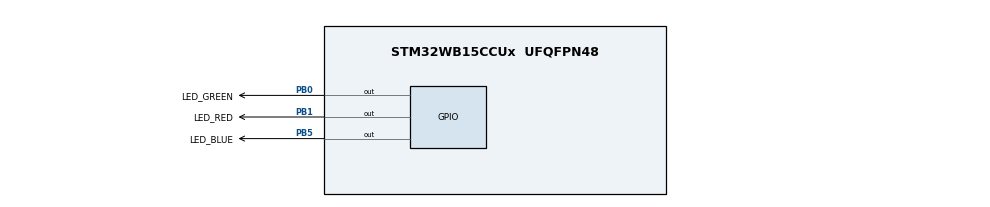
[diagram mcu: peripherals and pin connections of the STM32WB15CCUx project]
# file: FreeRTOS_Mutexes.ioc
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FREERTOS.HEAP_NUMBER=4
FREERTOS.INCLUDE_eTaskGetState=1
FREERTOS.INCLUDE_pcTaskGetTaskName=0
FREERTOS.INCLUDE_uxTaskGetStackHighWaterMark=1
FREERTOS.INCLUDE_uxTaskGetStackHighWaterMark2=0
FREERTOS.INCLUDE_uxTaskPriorityGet=1
FREERTOS.INCLUDE_vTaskCleanUpResources=0
FREERTOS.INCLUDE_vTaskDelay=1
FREERTOS.INCLUDE_vTaskDelayUntil=0
FREERTOS.INCLUDE_vTaskDelete=1
FREERTOS.INCLUDE_vTaskPrioritySet=1
FREERTOS.INCLUDE_vTaskSuspend=1
FREERTOS.INCLUDE_xEventGroupSetBitFromISR=0
FREERTOS.INCLUDE_xQueueGetMutexHolder=1
FREERTOS.INCLUDE_xSemaphoreGetMutexHolder=0
FREERTOS.INCLUDE_xTaskAbortDelay=0
FREERTOS.INCLUDE_xTaskGetCurrentTaskHandle=1
FREERTOS.INCLUDE_xTaskGetHandle=0
FREERTOS.INCLUDE_xTaskResumeFromISR=1
FREERTOS.MEMORY_ALLOCATION=0
FREERTOS.Mutexes01=osMutex
FREERTOS.Tasks01=MutHigh,16,128,MutexHighPriorityThreadr,Default,NULL,Dynamic,NULL,NULL;MutMedium,8,128,MutexMediumPriorityThread,Default,NULL,Dynamic,NULL,NULL;MutLow,8,128,MutexLowPriorityThread,Default,NULL,Dynamic,NULL,NULL
FREERTOS.configCHECK_FOR_STACK_OVERFLOW=0
FREERTOS.configENABLE_BACKWARD_COMPATIBILITY=1
FREERTOS.configENABLE_FPU=0
FREERTOS.configGENERATE_RUN_TIME_STATS=0
FREERTOS.configIDLE_SHOULD_YIELD=1
FREERTOS.configLIBRARY_LOWEST_INTERRUPT_PRIORITY=15
FREERTOS.configLIBRARY_MAX_SYSCALL_INTERRUPT_PRIORITY=5
FREERTOS.configMAX_CO_ROUTINE_PRIORITIES=2
FREERTOS.configMAX_PRIORITIES=56
FREERTOS.configMAX_TASK_NAME_LEN=16
FREERTOS.configMINIMAL_STACK_SIZE=128
FREERTOS.configQUEUE_REGISTRY_SIZE=8
FREERTOS.configRECORD_STACK_HIGH_ADDRESS=0
FREERTOS.configTICK_RATE_HZ=1000
FREERTOS.configTOTAL_HEAP_SIZE=3072
FREERTOS.configUSE_APPLICATION_TASK_TAG=0
FREERTOS.configUSE_COUNTING_SEMAPHORES=1
FREERTOS.configUSE_CO_ROUTINES=0
FREERTOS.configUSE_DAEMON_TASK_STARTUP_HOOK=0
FREERTOS.configUSE_IDLE_HOOK=0
FREERTOS.configUSE_MALLOC_FAILED_HOOK=0
FREERTOS.configUSE_MUTEXES=1
FREERTOS.configUSE_NEWLIB_REENTRANT=0
FREERTOS.configUSE_POSIX_ERRNO=0
FREERTOS.configUSE_PREEMPTION=0
FREERTOS.configUSE_RECURSIVE_MUTEXES=1
FREERTOS.configUSE_STATS_FORMATTING_FUNCTIONS=0
FREERTOS.configUSE_TASK_NOTIFICATIONS=1
FREERTOS.configUSE_TICKLESS_IDLE=0
FREERTOS.configUSE_TICK_HOOK=0
FREERTOS.configUSE_TIMERS=0
FREERTOS.configUSE_TRACE_FACILITY=1
FREERTOS.copyHeapFile=1
Mcu.Family=STM32WB
Mcu.Name=STM32WB15CCUx
Mcu.Package=UFQFPN48
NVIC.PriorityGroup=NVIC_PRIORITYGROUP_4
NVIC.TIM2_IRQn=true\:0\:0\:false\:false\:true\:false\:true\:true\:true
NVIC.TimeBase=TIM2_IRQn
NVIC.TimeBaseIP=TIM2
PB0.GPIO_Label=LED_GREEN
PB0.Signal=GPIO_Output
PB1.GPIO_Label=LED_RED
PB1.Signal=GPIO_Output
PB5.GPIO_Label=LED_BLUE
PB5.Signal=GPIO_Output
ProjectManager.HeapSize=0x200
ProjectManager.StackSize=0x400
ProjectManager.TargetToolchain=EWARM V9.60
RCC.AHB2CLKDivider=RCC_SYSCLK_DIV2
RCC.AHBFreq_Value=64000000
RCC.APB1Freq_Value=64000000
RCC.APB1TimFreq_Value=64000000
RCC.APB2Freq_Value=64000000
RCC.APB2TimFreq_Value=64000000
RCC.APB3Freq_Value=16000000
RCC.CortexFreq_Value=64000000
RCC.HCLKFreq_Value=64000000
RCC.HSE_VALUE=8000000
RCC.HSI_VALUE=16000000
RCC.LSE_VALUE=32768
RCC.PLLN=32
RCC.SYSCLKFreq_VALUE=64000000
RCC.SYSCLKSource=RCC_SYSCLKSOURCE_PLLCLK
RCC.VCOOutputFreq_Value=128000000
VP_FREERTOS_VS_CMSIS_V2.Mode=CMSIS_V2
VP_MEMORYMAP_VS_MEMORYMAP.Mode=CurAppReg
VP_SYS_VS_tim2.Mode=TIM2
board=custom

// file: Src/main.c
/* USER CODE BEGIN Header */
/**
  ******************************************************************************
  * @file    FreeRTOS/FreeRTOS_Mutexes/Src/main.c
  * @author  MCD Application Team
  * @brief   Main program body
  ******************************************************************************
  * @attention
  *
  * Copyright (c) 2019-2021 STMicroelectronics.
  * All rights reserved.
  *
  * This software is licensed under terms that can be found in the LICENSE file
  * in the root directory of this software component.
  * If no LICENSE file comes with this software, it is provided AS-IS.
  *
  ******************************************************************************
  */
/* USER CODE END Header */
#include "main.h"
#include "cmsis_os2.h"
#include "FreeRTOS.h"

/* USER CODE BEGIN Includes */

#include "task.h"
/* USER CODE END Includes */

/* USER CODE BEGIN PM */
#define mutexSHORT_DELAY     ((uint32_t) 20)
#define mutexNO_DELAY        ((uint32_t) 0)
#define mutexTWO_TICK_DELAY  ((uint32_t) 2)
/* USER CODE END PM */

/* Definitions for MutHigh */
osThreadId_t MutHighHandle;
const osThreadAttr_t MutHigh_attributes = {
  .name = "MutHigh",
  .priority = (osPriority_t) osPriorityBelowNormal,
  .stack_size = 128 * 4
};
/* Definitions for MutMedium */
osThreadId_t MutMediumHandle;
const osThreadAttr_t MutMedium_attributes = {
  .name = "MutMedium",
  .priority = (osPriority_t) osPriorityLow,
  .stack_size = 128 * 4
};
/* Definitions for MutLow */
osThreadId_t MutLowHandle;
const osThreadAttr_t MutLow_attributes = {
  .name = "MutLow",
  .priority = (osPriority_t) osPriorityLow,
  .stack_size = 128 * 4
};
/* Definitions for osMutex */
osMutexId_t osMutexHandle;
const osMutexAttr_t osMutex_attributes = {
  .name = "osMutex"
};
/* USER CODE BEGIN PV */

/* Variables used to detect and latch errors */
__IO uint32_t HighPriorityThreadCycles = 0, MediumPriorityThreadCycles = 0, LowPriorityThreadCycles = 0;
/* USER CODE END PV */

void SystemClock_Config(void);
void PeriphCommonClock_Config(void);
static void MX_GPIO_Init(void);
void MutexHighPriorityThreadr(void *argument);
void MutexMediumPriorityThread(void *argument);
void MutexLowPriorityThread(void *argument);

int main(void)
{

  /* USER CODE BEGIN 1 */
  /* STM32WBxx HAL library initialization:
       - Configure the Flash prefetch
       - Systick timer is configured by default as source of time base, but user
         can eventually implement his proper time base source (a general purpose
         timer for example or other time source), keeping in mind that Time base
         duration should be kept 1ms since PPP_TIMEOUT_VALUEs are defined and
         handled in milliseconds basis.
       - Set NVIC Group Priority to 4
       - Low Level Initialization
     */
  /* USER CODE END 1 */

  /* MCU Configuration--------------------------------------------------------*/

  /* Reset of all peripherals, Initializes the Flash interface and the Systick. */
  HAL_Init();

  /* Configure the system clock */
  SystemClock_Config();

  /* Configure the peripherals common clocks */
  PeriphCommonClock_Config();

  /* Initialize all configured peripherals */
  MX_GPIO_Init();

  /* Init scheduler */
  osKernelInitialize();
  /* Create the mutex(es) */
  /* creation of osMutex */
  osMutexHandle = osMutexNew(&osMutex_attributes);

  /* USER CODE BEGIN RTOS_MUTEX */
  if(osMutexHandle == NULL)
  {
    Error_Handler();
  }
  /* USER CODE END RTOS_MUTEX */

  /* Create the thread(s) */
  /* creation of MutHigh */
  MutHighHandle = osThreadNew(MutexHighPriorityThreadr, NULL, &MutHigh_attributes);

  /* creation of MutMedium */
  MutMediumHandle = osThreadNew(MutexMediumPriorityThread, NULL, &MutMedium_attributes);

  /* creation of MutLow */
  MutLowHandle = osThreadNew(MutexLowPriorityThread, NULL, &MutLow_attributes);

  /* USER CODE BEGIN RTOS_THREADS */
  if((MutHighHandle == NULL)||(MutMediumHandle == NULL)||(MutLowHandle == NULL))
  {
    Error_Handler();
  }
  /* USER CODE END RTOS_THREADS */

  /* Start scheduler */
  osKernelStart();

  /* We should never get here as control is now taken by the scheduler */

  /* Infinite loop */
  while (1)
  {

  }
}

void SystemClock_Config(void)
{
  RCC_OscInitTypeDef RCC_OscInitStruct = {0};
  RCC_ClkInitTypeDef RCC_ClkInitStruct = {0};

  /** Initializes the RCC Oscillators according to the specified parameters
  * in the RCC_OscInitTypeDef structure.
  */
  RCC_OscInitStruct.OscillatorType = RCC_OSCILLATORTYPE_HSI|RCC_OSCILLATORTYPE_MSI;
  RCC_OscInitStruct.HSIState = RCC_HSI_ON;
  RCC_OscInitStruct.MSIState = RCC_MSI_ON;
  RCC_OscInitStruct.HSICalibrationValue = RCC_HSICALIBRATION_DEFAULT;
  RCC_OscInitStruct.MSICalibrationValue = RCC_MSICALIBRATION_DEFAULT;
  RCC_OscInitStruct.MSIClockRange = RCC_MSIRANGE_6;
  RCC_OscInitStruct.PLL.PLLState = RCC_PLL_ON;
  RCC_OscInitStruct.PLL.PLLSource = RCC_PLLSOURCE_MSI;
  RCC_OscInitStruct.PLL.PLLM = RCC_PLLM_DIV1;
  RCC_OscInitStruct.PLL.PLLN = 32;
  RCC_OscInitStruct.PLL.PLLP = RCC_PLLP_DIV2;
  RCC_OscInitStruct.PLL.PLLR = RCC_PLLR_DIV2;
  RCC_OscInitStruct.PLL.PLLQ = RCC_PLLQ_DIV2;
  if (HAL_RCC_OscConfig(&RCC_OscInitStruct) != HAL_OK)
  {
    Error_Handler();
  }

  /** Configure the SYSCLKSource, HCLK, PCLK1 and PCLK2 clocks dividers
  */
  RCC_ClkInitStruct.ClockType = RCC_CLOCKTYPE_HCLK4|RCC_CLOCKTYPE_HCLK2
                              |RCC_CLOCKTYPE_HCLK|RCC_CLOCKTYPE_SYSCLK
                              |RCC_CLOCKTYPE_PCLK1|RCC_CLOCKTYPE_PCLK2;
  RCC_ClkInitStruct.SYSCLKSource = RCC_SYSCLKSOURCE_PLLCLK;
  RCC_ClkInitStruct.AHBCLKDivider = RCC_SYSCLK_DIV1;
  RCC_ClkInitStruct.APB1CLKDivider = RCC_HCLK_DIV1;
  RCC_ClkInitStruct.APB2CLKDivider = RCC_HCLK_DIV1;
  RCC_ClkInitStruct.AHBCLK2Divider = RCC_SYSCLK_DIV2;
  RCC_ClkInitStruct.AHBCLK4Divider = RCC_SYSCLK_DIV1;

  if (HAL_RCC_ClockConfig(&RCC_ClkInitStruct, FLASH_LATENCY_3) != HAL_OK)
  {
    Error_Handler();
  }
}

void PeriphCommonClock_Config(void)
{
  RCC_PeriphCLKInitTypeDef PeriphClkInitStruct = {0};

  /** Initializes the peripherals clock
  */
  PeriphClkInitStruct.PeriphClockSelection = RCC_PERIPHCLK_SMPS;
  PeriphClkInitStruct.SmpsClockSelection = RCC_SMPSCLKSOURCE_HSI;
  PeriphClkInitStruct.SmpsDivSelection = RCC_SMPSCLKDIV_RANGE1;

  if (HAL_RCCEx_PeriphCLKConfig(&PeriphClkInitStruct) != HAL_OK)
  {
    Error_Handler();
  }
}

static void MX_GPIO_Init(void)
{
  GPIO_InitTypeDef GPIO_InitStruct = {0};

  /* GPIO Ports Clock Enable */
  __HAL_RCC_GPIOB_CLK_ENABLE();

  /*Configure GPIO pin Output Level */
  HAL_GPIO_WritePin(GPIOB, LED_GREEN_Pin|LED_RED_Pin|LED_BLUE_Pin, GPIO_PIN_RESET);

  /*Configure GPIO pins : LED_GREEN_Pin LED_RED_Pin LED_BLUE_Pin */
  GPIO_InitStruct.Pin = LED_GREEN_Pin|LED_RED_Pin|LED_BLUE_Pin;
  GPIO_InitStruct.Mode = GPIO_MODE_OUTPUT_PP;
  GPIO_InitStruct.Pull = GPIO_NOPULL;
  GPIO_InitStruct.Speed = GPIO_SPEED_FREQ_LOW;
  HAL_GPIO_Init(GPIOB, &GPIO_InitStruct);

}

void MutexHighPriorityThreadr(void *argument)
{
  /* USER CODE BEGIN 5 */
  /* Just to remove compiler warning */
  (void) argument;
  /* Infinite loop */
  for (;;)
  {
    /* The first time through, the mutex will be immediately available. On
    subsequent times through, the mutex will be held by the low priority thread
    at this point and this will cause the low priority thread to inherit
    the priority of this thread. In this case the block time must be
    long enough to ensure the low priority thread will execute again before the
    block time expires.  If the block time does expire then the error
    flag will be set here */
    if (osMutexAcquire(osMutexHandle, mutexTWO_TICK_DELAY) != osOK)
    {
      /* Toggle LED_RED to indicate error */
      HAL_GPIO_TogglePin(LED_RED_GPIO_Port, LED_RED_Pin);
    }

    /* Ensure the other thread attempting to access the mutex
    are able to execute to ensure they either block (where a block
    time is specified) or return an error (where no block time is
    specified) as the mutex is held by this task */
    osDelay(mutexSHORT_DELAY);

    /* We should now be able to release the mutex .
    When the mutex is available again the medium priority thread
    should be unblocked but not run because it has a lower priority
    than this thread.  The low priority thread should also not run
    at this point as it too has a lower priority than this thread */
    if (osMutexRelease(osMutexHandle) != osOK)
    {
      /* Toggle LED_RED to indicate error */
      HAL_GPIO_TogglePin(LED_RED_GPIO_Port, LED_RED_Pin);
    }

    /* Keep count of the number of cycles this thread has performed */
    HighPriorityThreadCycles++;
    HAL_GPIO_TogglePin(LED_BLUE_GPIO_Port, LED_BLUE_Pin);

    /* Suspend ourselves to the medium priority thread can execute */
    osThreadSuspend(MutHighHandle);
  }
  /* USER CODE END 5 */
}

void MutexMediumPriorityThread(void *argument)
{
  /* USER CODE BEGIN MutexMediumPriorityThread */
  /* Just to remove compiler warning */
  (void) argument;

  /* Infinite loop */
  for (;;)
  {
    /* This thread will run while the high-priority thread is blocked, and the
    high-priority thread will block only once it has the mutex - therefore
    this call should block until the high-priority thread has given up the
    mutex, and not actually execute past this call until the high-priority
    thread is suspended */
    if (osMutexAcquire(osMutexHandle, osWaitForever) == osOK)
    {
      if (osThreadGetState(MutHighHandle) != osThreadBlocked)
      {
        /* Did not expect to execute until the high priority thread was
        suspended.
        Toggle LED_RED to indicate error */
        HAL_GPIO_TogglePin(LED_RED_GPIO_Port, LED_RED_Pin);
      }
      else
      {
        /* Give the mutex back before suspending ourselves to allow
        the low priority thread to obtain the mutex */
        if (osMutexRelease(osMutexHandle) != osOK)
        {
          /* Toggle LED_RED to indicate error */
          HAL_GPIO_TogglePin(LED_RED_GPIO_Port, LED_RED_Pin);
        }
        osThreadSuspend(MutMediumHandle);
      }
    }
    else
    {
      /* We should not leave the osMutexWait() function
      until the mutex was obtained.
      Toggle LED_RED to indicate error */
      HAL_GPIO_TogglePin(LED_RED_GPIO_Port, LED_RED_Pin);
    }

    /* The High and Medium priority threads should be in lock step */
    if (HighPriorityThreadCycles != (MediumPriorityThreadCycles + 1))
    {
      /* Toggle LED_RED to indicate error */
      HAL_GPIO_TogglePin(LED_RED_GPIO_Port, LED_RED_Pin);
    }

    /* Keep count of the number of cycles this task has performed so a
    stall can be detected */
    MediumPriorityThreadCycles++;
    HAL_GPIO_TogglePin(LED_GREEN_GPIO_Port, LED_GREEN_Pin);
  }
  /* USER CODE END MutexMediumPriorityThread */
}

void MutexLowPriorityThread(void *argument)
{
  /* USER CODE BEGIN MutexLowPriorityThread */
  /* Just to remove compiler warning */
  (void) argument;

  /* Infinite loop */
  for (;;)
  {
    /* Keep attempting to obtain the mutex.  We should only obtain it when
    the medium-priority thread has suspended itself, which in turn should only
    happen when the high-priority thread is also suspended */
    if (osMutexAcquire(osMutexHandle, mutexNO_DELAY) == osOK)
    {
      /* Is the haigh and medium-priority threads suspended? */
      if ((osThreadGetState(MutHighHandle) != osThreadBlocked) || (osThreadGetState(MutMediumHandle) != osThreadBlocked))
      {
        /* Toggle LED_RED to indicate error */
        HAL_GPIO_TogglePin(LED_RED_GPIO_Port, LED_RED_Pin);
      }
      else
      {
        /* Keep count of the number of cycles this task has performed
        so a stall can be detected */
        LowPriorityThreadCycles++;

        /* We can resume the other tasks here even though they have a
        higher priority than the this thread. When they execute they
        will attempt to obtain the mutex but fail because the low-priority
        thread is still the mutex holder.  this thread will then inherit
        the higher priority.  The medium-priority thread will block indefinitely
        when it attempts to obtain the mutex, the high-priority thread will only
        block for a fixed period and an error will be latched if the
        high-priority thread has not returned the mutex by the time this
        fixed period has expired */
        osThreadResume(MutMediumHandle);
        osThreadResume(MutHighHandle);

        /* The other two tasks should now have executed and no longer
        be suspended */
        if ((osThreadGetState(MutHighHandle) == osThreadBlocked) || (osThreadGetState(MutMediumHandle) == osThreadBlocked))
        {
          /* Toggle LED_RED to indicate error */
          HAL_GPIO_TogglePin(LED_RED_GPIO_Port, LED_RED_Pin);
        }

        /* Release the mutex, disinheriting the higher priority again */
        if (osMutexRelease(osMutexHandle) != osOK)
        {
          /* Toggle LED_RED to indicate error */
          HAL_GPIO_TogglePin(LED_RED_GPIO_Port, LED_RED_Pin);
        }
      }
    }

#if configUSE_PREEMPTION == 0
    {
      taskYIELD();
    }
#endif
  }
  /* USER CODE END MutexLowPriorityThread */
}

void HAL_TIM_PeriodElapsedCallback(TIM_HandleTypeDef *htim)
{
  if (htim->Instance == TIM2)
  {
    HAL_IncTick();
  }
}

void Error_Handler(void)
{
  while (1)
  {
  }
}
